# CBASS_MEM_CBASS_ISC_45830000h register map
Vendor: Texas Instruments
Peripheral module from a debugger description file (folder AM275x).
Registers are 32-bit, read-write, reset 0x0 unless marked. A register's access mark holds for its fields unless they carry their own. Offsets are as the file gives them; lines under a group give offsets from that group; [hi:lo] are bit positions; {n}, {i} and the like mark numbered series; 'fields as' and 'values as' point back to an identical list; <NAME> marks a mode.

## cbass_isc
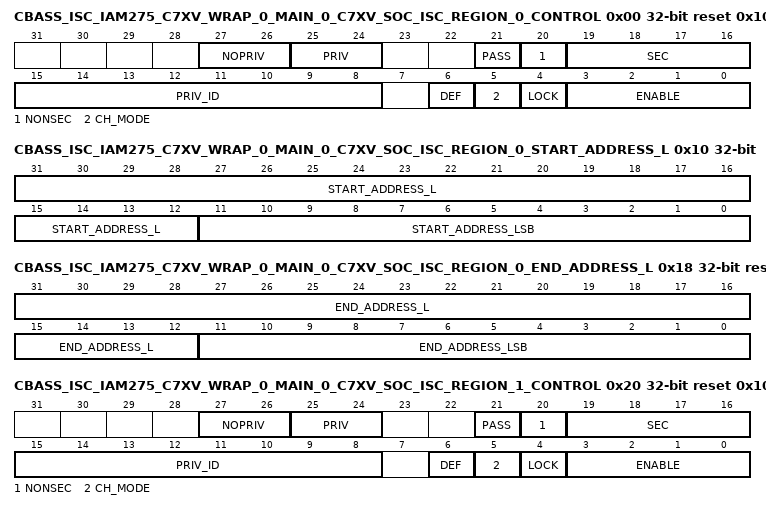
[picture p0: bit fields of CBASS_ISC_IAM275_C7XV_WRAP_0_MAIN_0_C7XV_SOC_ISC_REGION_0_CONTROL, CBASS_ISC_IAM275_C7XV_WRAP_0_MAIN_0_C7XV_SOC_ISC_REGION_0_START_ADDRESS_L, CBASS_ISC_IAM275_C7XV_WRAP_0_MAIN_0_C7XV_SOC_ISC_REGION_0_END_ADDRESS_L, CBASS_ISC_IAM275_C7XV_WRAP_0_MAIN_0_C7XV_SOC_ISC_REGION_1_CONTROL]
0x00 CBASS_ISC_IAM275_C7XV_WRAP_0_MAIN_0_C7XV_SOC_ISC_REGION_0_CONTROL access not given reset 0x102000 — The ISC Region 0 Control Register defines the control fields for the initiator Iam275_c7xv_wrap_0_main_0.c7xv_soc region 0 ISC.
  [27:26] NOPRIV rw — Clear output priv attribute. If each bit is set then the outgoing priv bit is cleared. Reset Source: domain_default_rst_mod_g_rst_n
  [25:24] PRIV rw — Set outgoing priv attribute. If each bit is set then the outgoing priv bit is set. Reset Source: domain_default_rst_mod_g_rst_n
  [21] PASS rw — No privID replacement, pass through value. Reset Source: domain_default_rst_mod_g_rst_n
  [20] NONSEC rw — Make outgoing non-secure. Reset Source: domain_default_rst_mod_g_rst_n
  [19:16] SEC rw — Make outgoing secure. A value of 0xA enables, others disable. Reset Source: domain_default_rst_mod_g_rst_n
  [15:8] PRIV_ID rw — Priv ID. Reset Source: domain_default_rst_mod_g_rst_n
  [6] DEF ro — Default region indication. The default region is used when all other regions do not match. Reset Source: domain_default_rst_mod_g_rst_n
  [5] CH_MODE rw — Enable channel mode to match region to a chanid value. Otherwise use address mode to match region to an address range. Reset Source: domain_default_rst_mod_g_rst_n
  [4] LOCK — Lock region. Once set the region values cannot be modified. Reset Source: domain_default_rst_mod_g_rst_n (access R/W1TS)
  [3:0] ENABLE rw — Enable region. A value of 0xA enables, others disable. Reset Source: domain_default_rst_mod_g_rst_n
0x10 CBASS_ISC_IAM275_C7XV_WRAP_0_MAIN_0_C7XV_SOC_ISC_REGION_0_START_ADDRESS_L — The ISC Region 0 Start Address Low Register defines the start address bits 31 to 0 for the initiator Iam275_c7xv_wrap_0_main_0.c7xv_soc region 0 ISC.
  [31:12] START_ADDRESS_L — Start address bits 31 to 12. Reset Source: domain_default_rst_mod_g_rst_n
  [11:0] START_ADDRESS_LSB — Start address bits 11 to 0 must be 0 as address must be 4KB aligned in address mode. Can also be channel number in channel mode. Reset Source: domain_default_rst_mod_g_rst_n
0x14 CBASS_ISC_IAM275_C7XV_WRAP_0_MAIN_0_C7XV_SOC_ISC_REGION_0_START_ADDRESS_H — The ISC Region 0 Start Address High Register defines the start address bits 47 to 32 for the initiator Iam275_c7xv_wrap_0_main_0.c7xv_soc region 0 ISC.
  [15:0] START_ADDRESS_H — Start address bits 47 to 32. Reset Source: domain_default_rst_mod_g_rst_n
0x18 CBASS_ISC_IAM275_C7XV_WRAP_0_MAIN_0_C7XV_SOC_ISC_REGION_0_END_ADDRESS_L access per field reset 0xFFF — The ISC Region 0 End Address Low Register defines the end included address bits 31 to 0 for the initiator Iam275_c7xv_wrap_0_main_0.c7xv_soc region 0 ISC.
  [31:12] END_ADDRESS_L rw — End address bits 31 to 12 to include in the match. Reset Source: domain_default_rst_mod_g_rst_n
  [11:0] END_ADDRESS_LSB ro — End address bits 11 to 0 are forced to Fs as address must be 4KB aligned. Reset Source: domain_default_rst_mod_g_rst_n
0x1C CBASS_ISC_IAM275_C7XV_WRAP_0_MAIN_0_C7XV_SOC_ISC_REGION_0_END_ADDRESS_H — The ISC Region 0 End Address High Register defines the end address bits 47 to 32 for the initiator Iam275_c7xv_wrap_0_main_0.c7xv_soc region 0 ISC.
  [15:0] END_ADDRESS_H — End address bits 47 to 32. Reset Source: domain_default_rst_mod_g_rst_n
0x20 CBASS_ISC_IAM275_C7XV_WRAP_0_MAIN_0_C7XV_SOC_ISC_REGION_1_CONTROL access not given reset 0x102000 — The ISC Region 1 Control Register defines the control fields for the initiator Iam275_c7xv_wrap_0_main_0.c7xv_soc region 1 ISC.
  fields as CBASS_ISC_IAM275_C7XV_WRAP_0_MAIN_0_C7XV_SOC_ISC_REGION_0_CONTROL
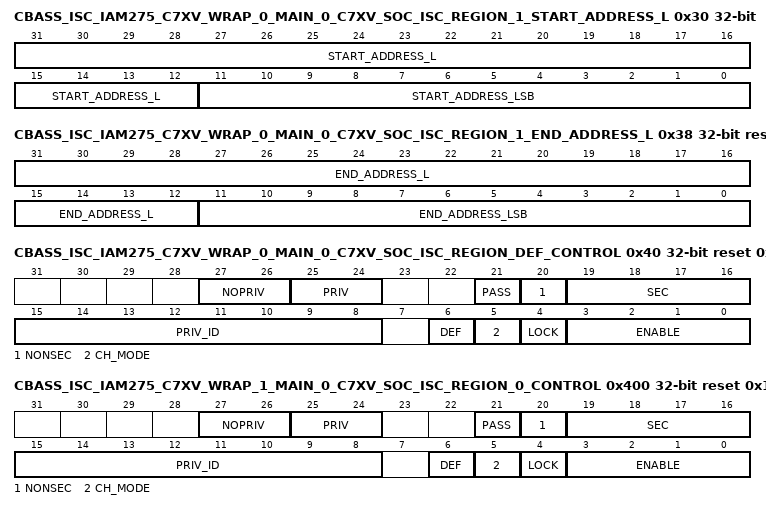
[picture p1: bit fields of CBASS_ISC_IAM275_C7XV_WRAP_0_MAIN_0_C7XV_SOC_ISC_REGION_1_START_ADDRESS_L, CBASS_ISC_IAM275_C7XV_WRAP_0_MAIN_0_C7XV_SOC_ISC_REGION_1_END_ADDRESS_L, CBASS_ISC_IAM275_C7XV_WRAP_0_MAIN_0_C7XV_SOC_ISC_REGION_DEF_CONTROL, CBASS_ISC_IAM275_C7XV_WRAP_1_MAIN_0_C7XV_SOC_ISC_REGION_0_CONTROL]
0x30 CBASS_ISC_IAM275_C7XV_WRAP_0_MAIN_0_C7XV_SOC_ISC_REGION_1_START_ADDRESS_L — The ISC Region 1 Start Address Low Register defines the start address bits 31 to 0 for the initiator Iam275_c7xv_wrap_0_main_0.c7xv_soc region 1 ISC.
  fields as CBASS_ISC_IAM275_C7XV_WRAP_0_MAIN_0_C7XV_SOC_ISC_REGION_0_START_ADDRESS_L
0x34 CBASS_ISC_IAM275_C7XV_WRAP_0_MAIN_0_C7XV_SOC_ISC_REGION_1_START_ADDRESS_H — The ISC Region 1 Start Address High Register defines the start address bits 47 to 32 for the initiator Iam275_c7xv_wrap_0_main_0.c7xv_soc region 1 ISC.
  fields as CBASS_ISC_IAM275_C7XV_WRAP_0_MAIN_0_C7XV_SOC_ISC_REGION_0_START_ADDRESS_H
0x38 CBASS_ISC_IAM275_C7XV_WRAP_0_MAIN_0_C7XV_SOC_ISC_REGION_1_END_ADDRESS_L access per field reset 0xFFF — The ISC Region 1 End Address Low Register defines the end included address bits 31 to 0 for the initiator Iam275_c7xv_wrap_0_main_0.c7xv_soc region 1 ISC.
  fields as CBASS_ISC_IAM275_C7XV_WRAP_0_MAIN_0_C7XV_SOC_ISC_REGION_0_END_ADDRESS_L
0x3C CBASS_ISC_IAM275_C7XV_WRAP_0_MAIN_0_C7XV_SOC_ISC_REGION_1_END_ADDRESS_H — The ISC Region 1 End Address High Register defines the end address bits 47 to 32 for the initiator Iam275_c7xv_wrap_0_main_0.c7xv_soc region 1 ISC.
  fields as CBASS_ISC_IAM275_C7XV_WRAP_0_MAIN_0_C7XV_SOC_ISC_REGION_0_END_ADDRESS_H
0x40 CBASS_ISC_IAM275_C7XV_WRAP_0_MAIN_0_C7XV_SOC_ISC_REGION_DEF_CONTROL access not given reset 0x10204A — The ISC Default Region Control Register defines the control fields for the initiator Iam275_c7xv_wrap_0_main_0.c7xv_soc region 2 ISC.
  [27:26] NOPRIV rw — Clear output priv attribute. If each bit is set then the outgoing priv bit is cleared, else the bit is unchanged. Do not set both priv and nopriv for the same bit. Reset Source: domain_default_rst_mod_g_rst_n
  [25:24] PRIV rw — Set outgoing priv attribute. If each bit is set then the outgoing priv bit is set, else the bit is unchanged. Do not set both priv and nopriv for the same bit. Reset Source: domain_default_rst_mod_g_rst_n
  [21] PASS rw — No privID replacement. A value of 1 will pass through privid value. A value of 0 will replace privid with priv_id field value. Reset Source: domain_default_rst_mod_g_rst_n
  [20] NONSEC rw — Make outgoing non-secure. A value of 1 forces secure clear, others do nothing. Do not set both sec and nonsec. Reset Source: domain_default_rst_mod_g_rst_n
  [19:16] SEC rw — Make outgoing secure. A value of 0xA forces secure set, others do nothing. Do not set both sec and nonsec. Reset Source: domain_default_rst_mod_g_rst_n
  [15:8] PRIV_ID rw — Priv ID value to use if pass is 0. Reset Source: domain_default_rst_mod_g_rst_n
  [6] DEF ro — Default region indication. The default region is used when all other regions do not match. Reset Source: domain_default_rst_mod_g_rst_n
  [5] CH_MODE ro — Enable channel mode to match region to a chanid value. Otherwise use address mode to match region to an address range. Reset Source: domain_default_rst_mod_g_rst_n
  [4] LOCK — Lock region. Once set, the region values cannot be modified. Reset Source: domain_default_rst_mod_g_rst_n (access R/W1TS)
  [3:0] ENABLE ro — Enable region. A value of 0xA enables, others disable. Reset Source: domain_default_rst_mod_g_rst_n
0x400 CBASS_ISC_IAM275_C7XV_WRAP_1_MAIN_0_C7XV_SOC_ISC_REGION_0_CONTROL access not given reset 0x102100 — The ISC Region 0 Control Register defines the control fields for the initiator Iam275_c7xv_wrap_1_main_0.c7xv_soc region 0 ISC.
  fields as CBASS_ISC_IAM275_C7XV_WRAP_0_MAIN_0_C7XV_SOC_ISC_REGION_0_CONTROL
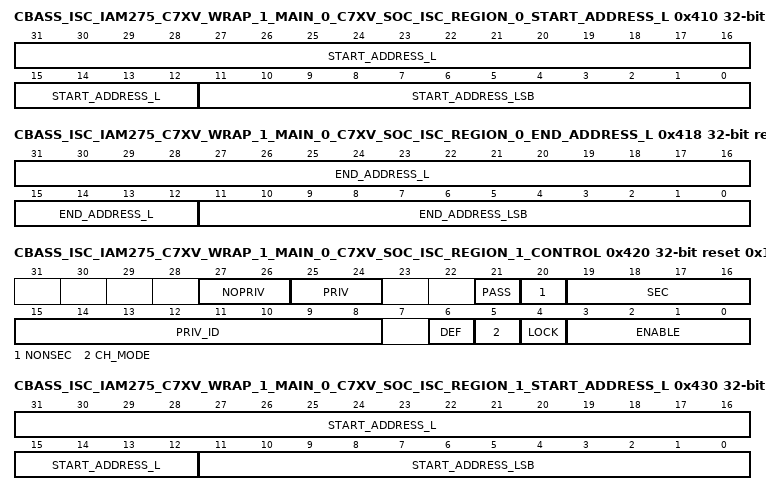
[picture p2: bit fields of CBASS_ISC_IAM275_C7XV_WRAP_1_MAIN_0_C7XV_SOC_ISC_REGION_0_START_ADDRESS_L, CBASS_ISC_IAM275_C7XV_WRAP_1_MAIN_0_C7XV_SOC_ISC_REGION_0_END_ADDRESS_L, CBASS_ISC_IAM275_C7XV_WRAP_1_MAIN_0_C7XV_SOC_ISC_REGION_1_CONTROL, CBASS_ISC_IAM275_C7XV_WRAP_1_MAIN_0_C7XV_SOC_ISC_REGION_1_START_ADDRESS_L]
0x410 CBASS_ISC_IAM275_C7XV_WRAP_1_MAIN_0_C7XV_SOC_ISC_REGION_0_START_ADDRESS_L — The ISC Region 0 Start Address Low Register defines the start address bits 31 to 0 for the initiator Iam275_c7xv_wrap_1_main_0.c7xv_soc region 0 ISC.
  fields as CBASS_ISC_IAM275_C7XV_WRAP_0_MAIN_0_C7XV_SOC_ISC_REGION_0_START_ADDRESS_L
0x414 CBASS_ISC_IAM275_C7XV_WRAP_1_MAIN_0_C7XV_SOC_ISC_REGION_0_START_ADDRESS_H — The ISC Region 0 Start Address High Register defines the start address bits 47 to 32 for the initiator Iam275_c7xv_wrap_1_main_0.c7xv_soc region 0 ISC.
  fields as CBASS_ISC_IAM275_C7XV_WRAP_0_MAIN_0_C7XV_SOC_ISC_REGION_0_START_ADDRESS_H
0x418 CBASS_ISC_IAM275_C7XV_WRAP_1_MAIN_0_C7XV_SOC_ISC_REGION_0_END_ADDRESS_L access per field reset 0xFFF — The ISC Region 0 End Address Low Register defines the end included address bits 31 to 0 for the initiator Iam275_c7xv_wrap_1_main_0.c7xv_soc region 0 ISC.
  fields as CBASS_ISC_IAM275_C7XV_WRAP_0_MAIN_0_C7XV_SOC_ISC_REGION_0_END_ADDRESS_L
0x41C CBASS_ISC_IAM275_C7XV_WRAP_1_MAIN_0_C7XV_SOC_ISC_REGION_0_END_ADDRESS_H — The ISC Region 0 End Address High Register defines the end address bits 47 to 32 for the initiator Iam275_c7xv_wrap_1_main_0.c7xv_soc region 0 ISC.
  fields as CBASS_ISC_IAM275_C7XV_WRAP_0_MAIN_0_C7XV_SOC_ISC_REGION_0_END_ADDRESS_H
0x420 CBASS_ISC_IAM275_C7XV_WRAP_1_MAIN_0_C7XV_SOC_ISC_REGION_1_CONTROL access not given reset 0x102100 — The ISC Region 1 Control Register defines the control fields for the initiator Iam275_c7xv_wrap_1_main_0.c7xv_soc region 1 ISC.
  fields as CBASS_ISC_IAM275_C7XV_WRAP_0_MAIN_0_C7XV_SOC_ISC_REGION_0_CONTROL
0x430 CBASS_ISC_IAM275_C7XV_WRAP_1_MAIN_0_C7XV_SOC_ISC_REGION_1_START_ADDRESS_L — The ISC Region 1 Start Address Low Register defines the start address bits 31 to 0 for the initiator Iam275_c7xv_wrap_1_main_0.c7xv_soc region 1 ISC.
  fields as CBASS_ISC_IAM275_C7XV_WRAP_0_MAIN_0_C7XV_SOC_ISC_REGION_0_START_ADDRESS_L
0x434 CBASS_ISC_IAM275_C7XV_WRAP_1_MAIN_0_C7XV_SOC_ISC_REGION_1_START_ADDRESS_H — The ISC Region 1 Start Address High Register defines the start address bits 47 to 32 for the initiator Iam275_c7xv_wrap_1_main_0.c7xv_soc region 1 ISC.
  fields as CBASS_ISC_IAM275_C7XV_WRAP_0_MAIN_0_C7XV_SOC_ISC_REGION_0_START_ADDRESS_H
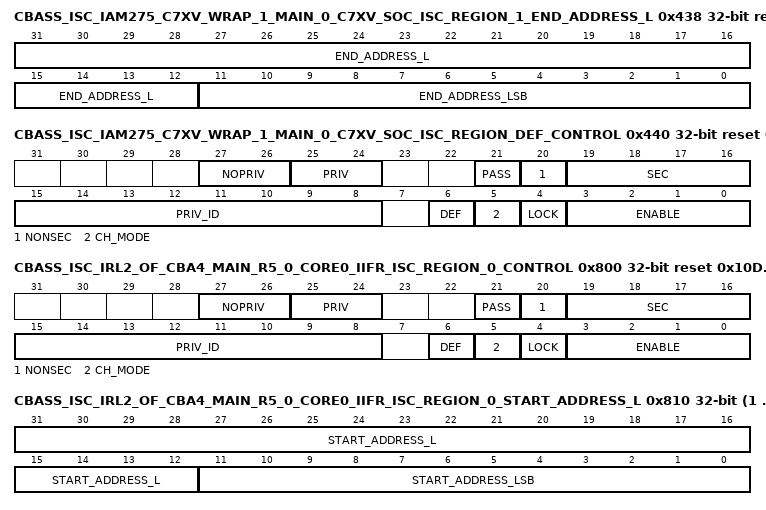
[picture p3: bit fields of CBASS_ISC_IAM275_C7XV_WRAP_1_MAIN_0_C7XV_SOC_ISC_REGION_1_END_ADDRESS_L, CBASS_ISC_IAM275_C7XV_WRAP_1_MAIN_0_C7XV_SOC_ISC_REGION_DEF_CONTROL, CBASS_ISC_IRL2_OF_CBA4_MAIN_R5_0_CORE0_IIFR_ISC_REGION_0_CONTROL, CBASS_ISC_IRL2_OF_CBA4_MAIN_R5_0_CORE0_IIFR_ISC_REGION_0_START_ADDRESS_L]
0x438 CBASS_ISC_IAM275_C7XV_WRAP_1_MAIN_0_C7XV_SOC_ISC_REGION_1_END_ADDRESS_L access per field reset 0xFFF — The ISC Region 1 End Address Low Register defines the end included address bits 31 to 0 for the initiator Iam275_c7xv_wrap_1_main_0.c7xv_soc region 1 ISC.
  fields as CBASS_ISC_IAM275_C7XV_WRAP_0_MAIN_0_C7XV_SOC_ISC_REGION_0_END_ADDRESS_L
0x43C CBASS_ISC_IAM275_C7XV_WRAP_1_MAIN_0_C7XV_SOC_ISC_REGION_1_END_ADDRESS_H — The ISC Region 1 End Address High Register defines the end address bits 47 to 32 for the initiator Iam275_c7xv_wrap_1_main_0.c7xv_soc region 1 ISC.
  fields as CBASS_ISC_IAM275_C7XV_WRAP_0_MAIN_0_C7XV_SOC_ISC_REGION_0_END_ADDRESS_H
0x440 CBASS_ISC_IAM275_C7XV_WRAP_1_MAIN_0_C7XV_SOC_ISC_REGION_DEF_CONTROL access not given reset 0x10214A — The ISC Default Region Control Register defines the control fields for the initiator Iam275_c7xv_wrap_1_main_0.c7xv_soc region 2 ISC.
  fields as CBASS_ISC_IAM275_C7XV_WRAP_0_MAIN_0_C7XV_SOC_ISC_REGION_DEF_CONTROL
{0x800+0x20*i} CBASS_ISC_IRL2_OF_CBA4_MAIN_R5_0_CORE0_IIFR_ISC_REGION_{i}_CONTROL access not given reset 0x10D800 (i=0..3) — The ISC Region {i} Control Register defines the control fields for the initiator Irl2_of_cba4_main_r5_0_core0.iifr region {i} ISC.
  fields as CBASS_ISC_IAM275_C7XV_WRAP_0_MAIN_0_C7XV_SOC_ISC_REGION_0_CONTROL
{0x810+0x20*i} CBASS_ISC_IRL2_OF_CBA4_MAIN_R5_0_CORE0_IIFR_ISC_REGION_{i}_START_ADDRESS_L (i=0..3) — The ISC Region {i} Start Address Low Register defines the start address bits 31 to 0 for the initiator Irl2_of_cba4_main_r5_0_core0.iifr region {i} ISC.
  fields as CBASS_ISC_IAM275_C7XV_WRAP_0_MAIN_0_C7XV_SOC_ISC_REGION_0_START_ADDRESS_L
{0x814+0x20*i} CBASS_ISC_IRL2_OF_CBA4_MAIN_R5_0_CORE0_IIFR_ISC_REGION_{i}_START_ADDRESS_H (i=0..3) — The ISC Region {i} Start Address High Register defines the start address bits 47 to 32 for the initiator Irl2_of_cba4_main_r5_0_core0.iifr region {i} ISC.
  fields as CBASS_ISC_IAM275_C7XV_WRAP_0_MAIN_0_C7XV_SOC_ISC_REGION_0_START_ADDRESS_H
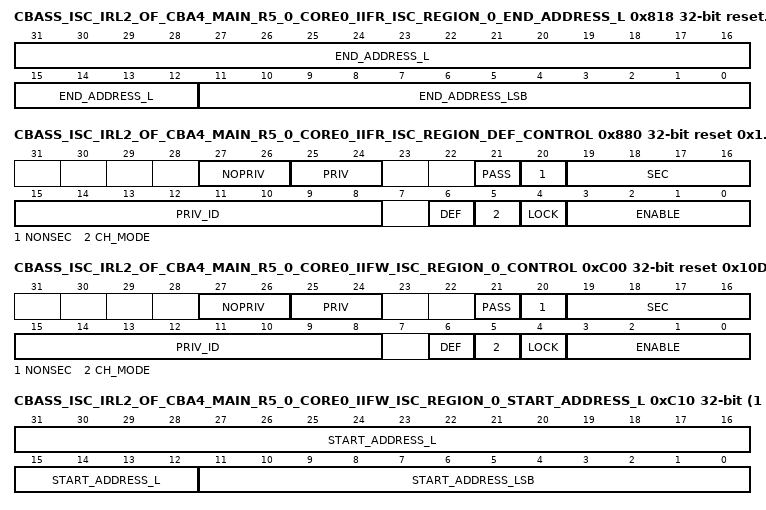
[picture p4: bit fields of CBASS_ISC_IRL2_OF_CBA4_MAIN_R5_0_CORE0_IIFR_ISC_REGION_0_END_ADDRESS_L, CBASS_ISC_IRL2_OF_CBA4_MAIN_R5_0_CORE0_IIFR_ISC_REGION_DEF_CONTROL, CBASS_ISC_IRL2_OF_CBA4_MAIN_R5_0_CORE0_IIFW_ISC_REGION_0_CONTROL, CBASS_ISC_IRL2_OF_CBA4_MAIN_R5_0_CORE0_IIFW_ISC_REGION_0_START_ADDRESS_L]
{0x818+0x20*i} CBASS_ISC_IRL2_OF_CBA4_MAIN_R5_0_CORE0_IIFR_ISC_REGION_{i}_END_ADDRESS_L access per field reset 0xFFF (i=0..3) — The ISC Region {i} End Address Low Register defines the end included address bits 31 to 0 for the initiator Irl2_of_cba4_main_r5_0_core0.iifr region {i} ISC.
  fields as CBASS_ISC_IAM275_C7XV_WRAP_0_MAIN_0_C7XV_SOC_ISC_REGION_0_END_ADDRESS_L
{0x81C+0x20*i} CBASS_ISC_IRL2_OF_CBA4_MAIN_R5_0_CORE0_IIFR_ISC_REGION_{i}_END_ADDRESS_H (i=0..3) — The ISC Region {i} End Address High Register defines the end address bits 47 to 32 for the initiator Irl2_of_cba4_main_r5_0_core0.iifr region {i} ISC.
  fields as CBASS_ISC_IAM275_C7XV_WRAP_0_MAIN_0_C7XV_SOC_ISC_REGION_0_END_ADDRESS_H
0x880 CBASS_ISC_IRL2_OF_CBA4_MAIN_R5_0_CORE0_IIFR_ISC_REGION_DEF_CONTROL access not given reset 0x10D84A — The ISC Default Region Control Register defines the control fields for the initiator Irl2_of_cba4_main_r5_0_core0.iifr region 4 ISC.
  fields as CBASS_ISC_IAM275_C7XV_WRAP_0_MAIN_0_C7XV_SOC_ISC_REGION_DEF_CONTROL
{0xC00+0x20*i} CBASS_ISC_IRL2_OF_CBA4_MAIN_R5_0_CORE0_IIFW_ISC_REGION_{i}_CONTROL access not given reset 0x10D800 (i=0..3) — The ISC Region {i} Control Register defines the control fields for the initiator Irl2_of_cba4_main_r5_0_core0.iifw region {i} ISC.
  fields as CBASS_ISC_IAM275_C7XV_WRAP_0_MAIN_0_C7XV_SOC_ISC_REGION_0_CONTROL
{0xC10+0x20*i} CBASS_ISC_IRL2_OF_CBA4_MAIN_R5_0_CORE0_IIFW_ISC_REGION_{i}_START_ADDRESS_L (i=0..3) — The ISC Region {i} Start Address Low Register defines the start address bits 31 to 0 for the initiator Irl2_of_cba4_main_r5_0_core0.iifw region {i} ISC.
  fields as CBASS_ISC_IAM275_C7XV_WRAP_0_MAIN_0_C7XV_SOC_ISC_REGION_0_START_ADDRESS_L
{0xC14+0x20*i} CBASS_ISC_IRL2_OF_CBA4_MAIN_R5_0_CORE0_IIFW_ISC_REGION_{i}_START_ADDRESS_H (i=0..3) — The ISC Region {i} Start Address High Register defines the start address bits 47 to 32 for the initiator Irl2_of_cba4_main_r5_0_core0.iifw region {i} ISC.
  fields as CBASS_ISC_IAM275_C7XV_WRAP_0_MAIN_0_C7XV_SOC_ISC_REGION_0_START_ADDRESS_H
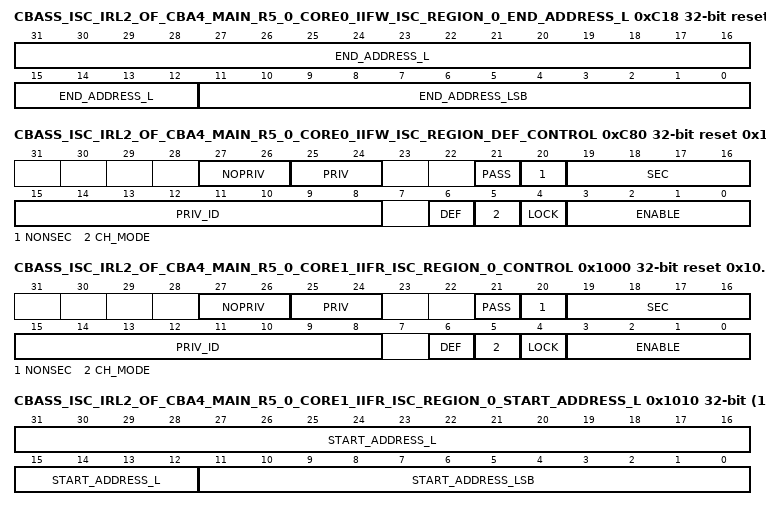
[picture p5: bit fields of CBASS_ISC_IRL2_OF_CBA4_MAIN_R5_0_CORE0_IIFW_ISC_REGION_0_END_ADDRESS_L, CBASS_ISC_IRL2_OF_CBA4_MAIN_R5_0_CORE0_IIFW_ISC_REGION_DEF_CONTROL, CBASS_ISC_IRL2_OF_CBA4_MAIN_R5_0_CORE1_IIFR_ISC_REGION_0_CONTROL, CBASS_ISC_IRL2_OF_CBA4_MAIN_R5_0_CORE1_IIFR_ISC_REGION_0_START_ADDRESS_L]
{0xC18+0x20*i} CBASS_ISC_IRL2_OF_CBA4_MAIN_R5_0_CORE0_IIFW_ISC_REGION_{i}_END_ADDRESS_L access per field reset 0xFFF (i=0..3) — The ISC Region {i} End Address Low Register defines the end included address bits 31 to 0 for the initiator Irl2_of_cba4_main_r5_0_core0.iifw region {i} ISC.
  fields as CBASS_ISC_IAM275_C7XV_WRAP_0_MAIN_0_C7XV_SOC_ISC_REGION_0_END_ADDRESS_L
{0xC1C+0x20*i} CBASS_ISC_IRL2_OF_CBA4_MAIN_R5_0_CORE0_IIFW_ISC_REGION_{i}_END_ADDRESS_H (i=0..3) — The ISC Region {i} End Address High Register defines the end address bits 47 to 32 for the initiator Irl2_of_cba4_main_r5_0_core0.iifw region {i} ISC.
  fields as CBASS_ISC_IAM275_C7XV_WRAP_0_MAIN_0_C7XV_SOC_ISC_REGION_0_END_ADDRESS_H
0xC80 CBASS_ISC_IRL2_OF_CBA4_MAIN_R5_0_CORE0_IIFW_ISC_REGION_DEF_CONTROL access not given reset 0x10D84A — The ISC Default Region Control Register defines the control fields for the initiator Irl2_of_cba4_main_r5_0_core0.iifw region 4 ISC.
  fields as CBASS_ISC_IAM275_C7XV_WRAP_0_MAIN_0_C7XV_SOC_ISC_REGION_DEF_CONTROL
{0x1000+0x20*i} CBASS_ISC_IRL2_OF_CBA4_MAIN_R5_0_CORE1_IIFR_ISC_REGION_{i}_CONTROL access not given reset 0x10D900 (i=0..3) — The ISC Region {i} Control Register defines the control fields for the initiator Irl2_of_cba4_main_r5_0_core1.iifr region {i} ISC.
  fields as CBASS_ISC_IAM275_C7XV_WRAP_0_MAIN_0_C7XV_SOC_ISC_REGION_0_CONTROL
{0x1010+0x20*i} CBASS_ISC_IRL2_OF_CBA4_MAIN_R5_0_CORE1_IIFR_ISC_REGION_{i}_START_ADDRESS_L (i=0..3) — The ISC Region {i} Start Address Low Register defines the start address bits 31 to 0 for the initiator Irl2_of_cba4_main_r5_0_core1.iifr region {i} ISC.
  fields as CBASS_ISC_IAM275_C7XV_WRAP_0_MAIN_0_C7XV_SOC_ISC_REGION_0_START_ADDRESS_L
{0x1014+0x20*i} CBASS_ISC_IRL2_OF_CBA4_MAIN_R5_0_CORE1_IIFR_ISC_REGION_{i}_START_ADDRESS_H (i=0..3) — The ISC Region {i} Start Address High Register defines the start address bits 47 to 32 for the initiator Irl2_of_cba4_main_r5_0_core1.iifr region {i} ISC.
  fields as CBASS_ISC_IAM275_C7XV_WRAP_0_MAIN_0_C7XV_SOC_ISC_REGION_0_START_ADDRESS_H
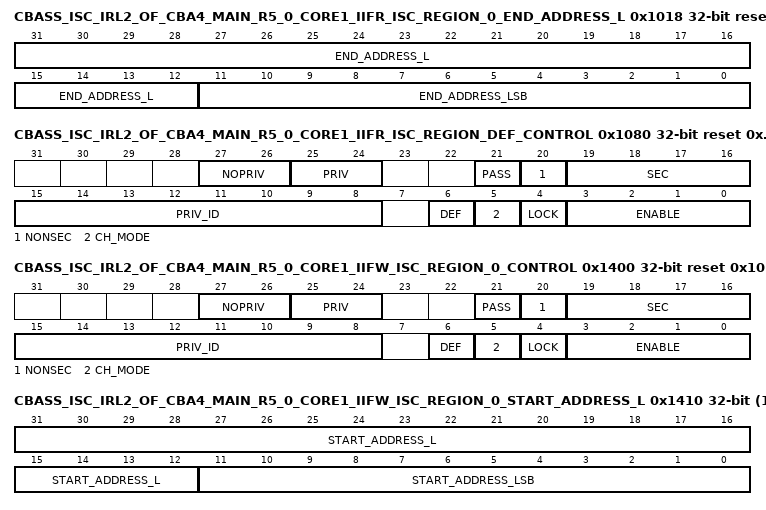
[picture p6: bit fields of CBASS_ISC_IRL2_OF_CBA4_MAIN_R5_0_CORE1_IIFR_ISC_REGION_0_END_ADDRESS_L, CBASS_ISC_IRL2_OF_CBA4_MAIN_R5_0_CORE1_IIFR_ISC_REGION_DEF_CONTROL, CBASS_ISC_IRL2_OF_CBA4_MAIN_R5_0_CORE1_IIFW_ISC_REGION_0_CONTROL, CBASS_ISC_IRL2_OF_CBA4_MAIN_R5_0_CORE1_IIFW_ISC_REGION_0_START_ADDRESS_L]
{0x1018+0x20*i} CBASS_ISC_IRL2_OF_CBA4_MAIN_R5_0_CORE1_IIFR_ISC_REGION_{i}_END_ADDRESS_L access per field reset 0xFFF (i=0..3) — The ISC Region {i} End Address Low Register defines the end included address bits 31 to 0 for the initiator Irl2_of_cba4_main_r5_0_core1.iifr region {i} ISC.
  fields as CBASS_ISC_IAM275_C7XV_WRAP_0_MAIN_0_C7XV_SOC_ISC_REGION_0_END_ADDRESS_L
{0x101C+0x20*i} CBASS_ISC_IRL2_OF_CBA4_MAIN_R5_0_CORE1_IIFR_ISC_REGION_{i}_END_ADDRESS_H (i=0..3) — The ISC Region {i} End Address High Register defines the end address bits 47 to 32 for the initiator Irl2_of_cba4_main_r5_0_core1.iifr region {i} ISC.
  fields as CBASS_ISC_IAM275_C7XV_WRAP_0_MAIN_0_C7XV_SOC_ISC_REGION_0_END_ADDRESS_H
0x1080 CBASS_ISC_IRL2_OF_CBA4_MAIN_R5_0_CORE1_IIFR_ISC_REGION_DEF_CONTROL access not given reset 0x10D94A — The ISC Default Region Control Register defines the control fields for the initiator Irl2_of_cba4_main_r5_0_core1.iifr region 4 ISC.
  fields as CBASS_ISC_IAM275_C7XV_WRAP_0_MAIN_0_C7XV_SOC_ISC_REGION_DEF_CONTROL
{0x1400+0x20*i} CBASS_ISC_IRL2_OF_CBA4_MAIN_R5_0_CORE1_IIFW_ISC_REGION_{i}_CONTROL access not given reset 0x10D900 (i=0..3) — The ISC Region {i} Control Register defines the control fields for the initiator Irl2_of_cba4_main_r5_0_core1.iifw region {i} ISC.
  fields as CBASS_ISC_IAM275_C7XV_WRAP_0_MAIN_0_C7XV_SOC_ISC_REGION_0_CONTROL
{0x1410+0x20*i} CBASS_ISC_IRL2_OF_CBA4_MAIN_R5_0_CORE1_IIFW_ISC_REGION_{i}_START_ADDRESS_L (i=0..3) — The ISC Region {i} Start Address Low Register defines the start address bits 31 to 0 for the initiator Irl2_of_cba4_main_r5_0_core1.iifw region {i} ISC.
  fields as CBASS_ISC_IAM275_C7XV_WRAP_0_MAIN_0_C7XV_SOC_ISC_REGION_0_START_ADDRESS_L
{0x1414+0x20*i} CBASS_ISC_IRL2_OF_CBA4_MAIN_R5_0_CORE1_IIFW_ISC_REGION_{i}_START_ADDRESS_H (i=0..3) — The ISC Region {i} Start Address High Register defines the start address bits 47 to 32 for the initiator Irl2_of_cba4_main_r5_0_core1.iifw region {i} ISC.
  fields as CBASS_ISC_IAM275_C7XV_WRAP_0_MAIN_0_C7XV_SOC_ISC_REGION_0_START_ADDRESS_H
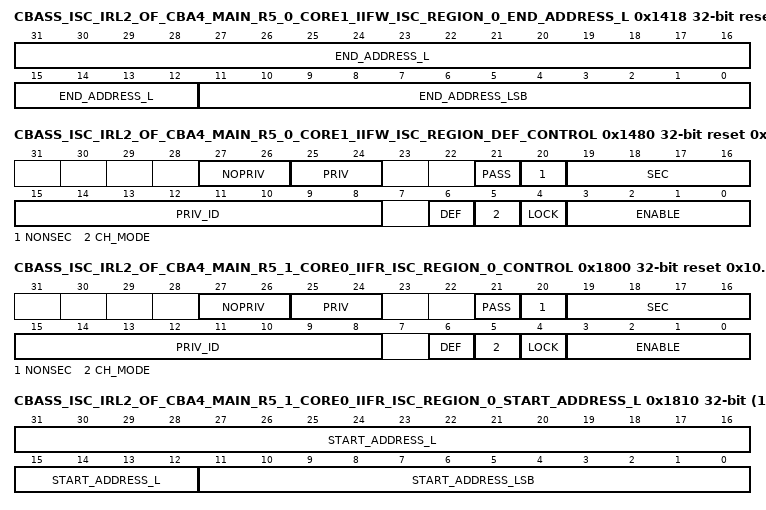
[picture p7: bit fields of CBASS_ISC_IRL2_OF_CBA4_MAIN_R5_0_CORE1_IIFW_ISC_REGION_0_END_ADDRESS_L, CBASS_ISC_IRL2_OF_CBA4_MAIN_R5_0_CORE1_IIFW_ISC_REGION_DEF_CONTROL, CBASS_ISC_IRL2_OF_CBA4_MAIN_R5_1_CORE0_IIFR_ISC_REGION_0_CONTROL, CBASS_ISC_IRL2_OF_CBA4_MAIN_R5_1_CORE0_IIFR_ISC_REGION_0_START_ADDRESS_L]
{0x1418+0x20*i} CBASS_ISC_IRL2_OF_CBA4_MAIN_R5_0_CORE1_IIFW_ISC_REGION_{i}_END_ADDRESS_L access per field reset 0xFFF (i=0..3) — The ISC Region {i} End Address Low Register defines the end included address bits 31 to 0 for the initiator Irl2_of_cba4_main_r5_0_core1.iifw region {i} ISC.
  fields as CBASS_ISC_IAM275_C7XV_WRAP_0_MAIN_0_C7XV_SOC_ISC_REGION_0_END_ADDRESS_L
{0x141C+0x20*i} CBASS_ISC_IRL2_OF_CBA4_MAIN_R5_0_CORE1_IIFW_ISC_REGION_{i}_END_ADDRESS_H (i=0..3) — The ISC Region {i} End Address High Register defines the end address bits 47 to 32 for the initiator Irl2_of_cba4_main_r5_0_core1.iifw region {i} ISC.
  fields as CBASS_ISC_IAM275_C7XV_WRAP_0_MAIN_0_C7XV_SOC_ISC_REGION_0_END_ADDRESS_H
0x1480 CBASS_ISC_IRL2_OF_CBA4_MAIN_R5_0_CORE1_IIFW_ISC_REGION_DEF_CONTROL access not given reset 0x10D94A — The ISC Default Region Control Register defines the control fields for the initiator Irl2_of_cba4_main_r5_0_core1.iifw region 4 ISC.
  fields as CBASS_ISC_IAM275_C7XV_WRAP_0_MAIN_0_C7XV_SOC_ISC_REGION_DEF_CONTROL
{0x1800+0x20*i} CBASS_ISC_IRL2_OF_CBA4_MAIN_R5_1_CORE0_IIFR_ISC_REGION_{i}_CONTROL access not given reset 0x10DB00 (i=0..3) — The ISC Region {i} Control Register defines the control fields for the initiator Irl2_of_cba4_main_r5_1_core0.iifr region {i} ISC.
  fields as CBASS_ISC_IAM275_C7XV_WRAP_0_MAIN_0_C7XV_SOC_ISC_REGION_0_CONTROL
{0x1810+0x20*i} CBASS_ISC_IRL2_OF_CBA4_MAIN_R5_1_CORE0_IIFR_ISC_REGION_{i}_START_ADDRESS_L (i=0..3) — The ISC Region {i} Start Address Low Register defines the start address bits 31 to 0 for the initiator Irl2_of_cba4_main_r5_1_core0.iifr region {i} ISC.
  fields as CBASS_ISC_IAM275_C7XV_WRAP_0_MAIN_0_C7XV_SOC_ISC_REGION_0_START_ADDRESS_L
{0x1814+0x20*i} CBASS_ISC_IRL2_OF_CBA4_MAIN_R5_1_CORE0_IIFR_ISC_REGION_{i}_START_ADDRESS_H (i=0..3) — The ISC Region {i} Start Address High Register defines the start address bits 47 to 32 for the initiator Irl2_of_cba4_main_r5_1_core0.iifr region {i} ISC.
  fields as CBASS_ISC_IAM275_C7XV_WRAP_0_MAIN_0_C7XV_SOC_ISC_REGION_0_START_ADDRESS_H
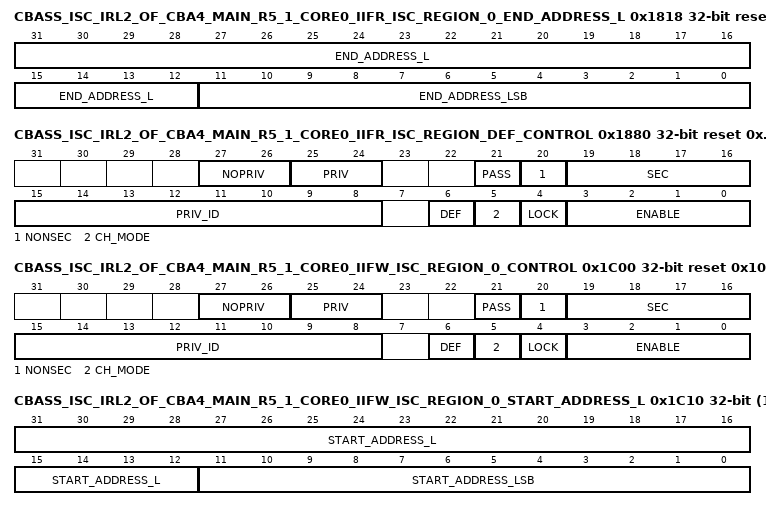
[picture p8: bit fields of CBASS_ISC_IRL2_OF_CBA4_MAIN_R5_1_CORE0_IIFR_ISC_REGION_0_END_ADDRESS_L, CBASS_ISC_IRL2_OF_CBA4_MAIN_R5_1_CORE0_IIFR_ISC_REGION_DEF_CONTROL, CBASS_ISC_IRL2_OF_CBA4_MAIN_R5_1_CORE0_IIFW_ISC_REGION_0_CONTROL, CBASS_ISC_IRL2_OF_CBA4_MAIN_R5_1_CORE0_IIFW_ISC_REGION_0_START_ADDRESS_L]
{0x1818+0x20*i} CBASS_ISC_IRL2_OF_CBA4_MAIN_R5_1_CORE0_IIFR_ISC_REGION_{i}_END_ADDRESS_L access per field reset 0xFFF (i=0..3) — The ISC Region {i} End Address Low Register defines the end included address bits 31 to 0 for the initiator Irl2_of_cba4_main_r5_1_core0.iifr region {i} ISC.
  fields as CBASS_ISC_IAM275_C7XV_WRAP_0_MAIN_0_C7XV_SOC_ISC_REGION_0_END_ADDRESS_L
{0x181C+0x20*i} CBASS_ISC_IRL2_OF_CBA4_MAIN_R5_1_CORE0_IIFR_ISC_REGION_{i}_END_ADDRESS_H (i=0..3) — The ISC Region {i} End Address High Register defines the end address bits 47 to 32 for the initiator Irl2_of_cba4_main_r5_1_core0.iifr region {i} ISC.
  fields as CBASS_ISC_IAM275_C7XV_WRAP_0_MAIN_0_C7XV_SOC_ISC_REGION_0_END_ADDRESS_H
0x1880 CBASS_ISC_IRL2_OF_CBA4_MAIN_R5_1_CORE0_IIFR_ISC_REGION_DEF_CONTROL access not given reset 0x10DB4A — The ISC Default Region Control Register defines the control fields for the initiator Irl2_of_cba4_main_r5_1_core0.iifr region 4 ISC.
  fields as CBASS_ISC_IAM275_C7XV_WRAP_0_MAIN_0_C7XV_SOC_ISC_REGION_DEF_CONTROL
{0x1C00+0x20*i} CBASS_ISC_IRL2_OF_CBA4_MAIN_R5_1_CORE0_IIFW_ISC_REGION_{i}_CONTROL access not given reset 0x10DB00 (i=0..3) — The ISC Region {i} Control Register defines the control fields for the initiator Irl2_of_cba4_main_r5_1_core0.iifw region {i} ISC.
  fields as CBASS_ISC_IAM275_C7XV_WRAP_0_MAIN_0_C7XV_SOC_ISC_REGION_0_CONTROL
{0x1C10+0x20*i} CBASS_ISC_IRL2_OF_CBA4_MAIN_R5_1_CORE0_IIFW_ISC_REGION_{i}_START_ADDRESS_L (i=0..3) — The ISC Region {i} Start Address Low Register defines the start address bits 31 to 0 for the initiator Irl2_of_cba4_main_r5_1_core0.iifw region {i} ISC.
  fields as CBASS_ISC_IAM275_C7XV_WRAP_0_MAIN_0_C7XV_SOC_ISC_REGION_0_START_ADDRESS_L
{0x1C14+0x20*i} CBASS_ISC_IRL2_OF_CBA4_MAIN_R5_1_CORE0_IIFW_ISC_REGION_{i}_START_ADDRESS_H (i=0..3) — The ISC Region {i} Start Address High Register defines the start address bits 47 to 32 for the initiator Irl2_of_cba4_main_r5_1_core0.iifw region {i} ISC.
  fields as CBASS_ISC_IAM275_C7XV_WRAP_0_MAIN_0_C7XV_SOC_ISC_REGION_0_START_ADDRESS_H
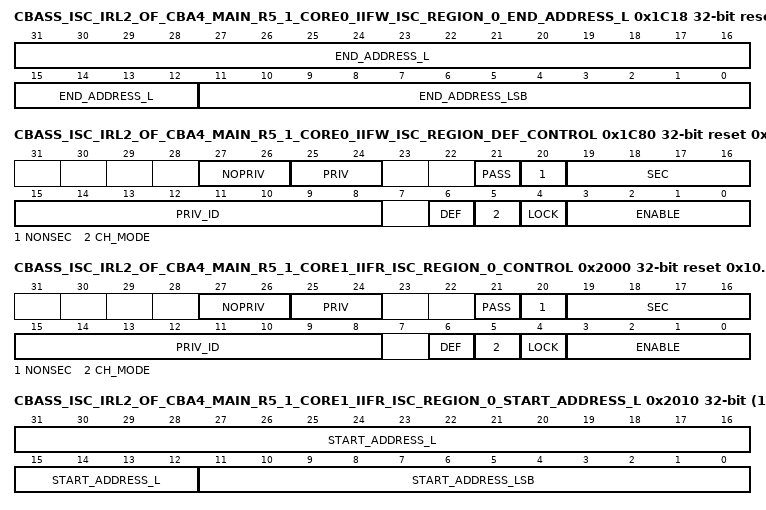
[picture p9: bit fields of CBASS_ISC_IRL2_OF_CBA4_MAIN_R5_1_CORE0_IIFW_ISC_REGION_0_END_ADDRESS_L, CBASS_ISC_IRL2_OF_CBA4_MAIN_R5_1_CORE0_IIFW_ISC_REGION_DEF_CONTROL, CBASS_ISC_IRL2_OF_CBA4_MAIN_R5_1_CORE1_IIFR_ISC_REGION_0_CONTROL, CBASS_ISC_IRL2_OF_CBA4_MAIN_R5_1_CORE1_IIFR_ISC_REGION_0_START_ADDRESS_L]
{0x1C18+0x20*i} CBASS_ISC_IRL2_OF_CBA4_MAIN_R5_1_CORE0_IIFW_ISC_REGION_{i}_END_ADDRESS_L access per field reset 0xFFF (i=0..3) — The ISC Region {i} End Address Low Register defines the end included address bits 31 to 0 for the initiator Irl2_of_cba4_main_r5_1_core0.iifw region {i} ISC.
  fields as CBASS_ISC_IAM275_C7XV_WRAP_0_MAIN_0_C7XV_SOC_ISC_REGION_0_END_ADDRESS_L
{0x1C1C+0x20*i} CBASS_ISC_IRL2_OF_CBA4_MAIN_R5_1_CORE0_IIFW_ISC_REGION_{i}_END_ADDRESS_H (i=0..3) — The ISC Region {i} End Address High Register defines the end address bits 47 to 32 for the initiator Irl2_of_cba4_main_r5_1_core0.iifw region {i} ISC.
  fields as CBASS_ISC_IAM275_C7XV_WRAP_0_MAIN_0_C7XV_SOC_ISC_REGION_0_END_ADDRESS_H
0x1C80 CBASS_ISC_IRL2_OF_CBA4_MAIN_R5_1_CORE0_IIFW_ISC_REGION_DEF_CONTROL access not given reset 0x10DB4A — The ISC Default Region Control Register defines the control fields for the initiator Irl2_of_cba4_main_r5_1_core0.iifw region 4 ISC.
  fields as CBASS_ISC_IAM275_C7XV_WRAP_0_MAIN_0_C7XV_SOC_ISC_REGION_DEF_CONTROL
{0x2000+0x20*i} CBASS_ISC_IRL2_OF_CBA4_MAIN_R5_1_CORE1_IIFR_ISC_REGION_{i}_CONTROL access not given reset 0x10DC00 (i=0..3) — The ISC Region {i} Control Register defines the control fields for the initiator Irl2_of_cba4_main_r5_1_core1.iifr region {i} ISC.
  fields as CBASS_ISC_IAM275_C7XV_WRAP_0_MAIN_0_C7XV_SOC_ISC_REGION_0_CONTROL
{0x2010+0x20*i} CBASS_ISC_IRL2_OF_CBA4_MAIN_R5_1_CORE1_IIFR_ISC_REGION_{i}_START_ADDRESS_L (i=0..3) — The ISC Region {i} Start Address Low Register defines the start address bits 31 to 0 for the initiator Irl2_of_cba4_main_r5_1_core1.iifr region {i} ISC.
  fields as CBASS_ISC_IAM275_C7XV_WRAP_0_MAIN_0_C7XV_SOC_ISC_REGION_0_START_ADDRESS_L
{0x2014+0x20*i} CBASS_ISC_IRL2_OF_CBA4_MAIN_R5_1_CORE1_IIFR_ISC_REGION_{i}_START_ADDRESS_H (i=0..3) — The ISC Region {i} Start Address High Register defines the start address bits 47 to 32 for the initiator Irl2_of_cba4_main_r5_1_core1.iifr region {i} ISC.
  fields as CBASS_ISC_IAM275_C7XV_WRAP_0_MAIN_0_C7XV_SOC_ISC_REGION_0_START_ADDRESS_H
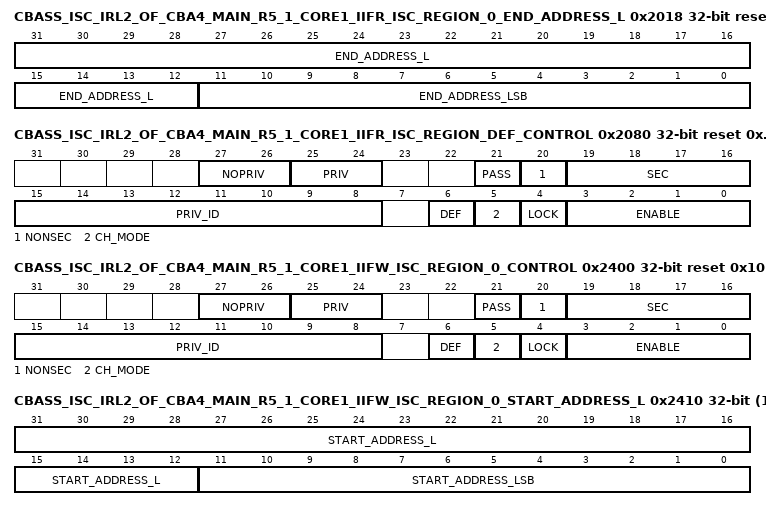
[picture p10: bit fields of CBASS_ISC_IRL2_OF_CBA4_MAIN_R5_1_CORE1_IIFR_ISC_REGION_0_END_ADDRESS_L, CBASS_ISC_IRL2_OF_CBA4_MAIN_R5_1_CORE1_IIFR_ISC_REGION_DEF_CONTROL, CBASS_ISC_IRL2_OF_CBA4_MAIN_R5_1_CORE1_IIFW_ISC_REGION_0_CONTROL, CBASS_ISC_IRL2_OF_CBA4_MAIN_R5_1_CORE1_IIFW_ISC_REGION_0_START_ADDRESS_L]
{0x2018+0x20*i} CBASS_ISC_IRL2_OF_CBA4_MAIN_R5_1_CORE1_IIFR_ISC_REGION_{i}_END_ADDRESS_L access per field reset 0xFFF (i=0..3) — The ISC Region {i} End Address Low Register defines the end included address bits 31 to 0 for the initiator Irl2_of_cba4_main_r5_1_core1.iifr region {i} ISC.
  fields as CBASS_ISC_IAM275_C7XV_WRAP_0_MAIN_0_C7XV_SOC_ISC_REGION_0_END_ADDRESS_L
{0x201C+0x20*i} CBASS_ISC_IRL2_OF_CBA4_MAIN_R5_1_CORE1_IIFR_ISC_REGION_{i}_END_ADDRESS_H (i=0..3) — The ISC Region {i} End Address High Register defines the end address bits 47 to 32 for the initiator Irl2_of_cba4_main_r5_1_core1.iifr region {i} ISC.
  fields as CBASS_ISC_IAM275_C7XV_WRAP_0_MAIN_0_C7XV_SOC_ISC_REGION_0_END_ADDRESS_H
0x2080 CBASS_ISC_IRL2_OF_CBA4_MAIN_R5_1_CORE1_IIFR_ISC_REGION_DEF_CONTROL access not given reset 0x10DC4A — The ISC Default Region Control Register defines the control fields for the initiator Irl2_of_cba4_main_r5_1_core1.iifr region 4 ISC.
  fields as CBASS_ISC_IAM275_C7XV_WRAP_0_MAIN_0_C7XV_SOC_ISC_REGION_DEF_CONTROL
{0x2400+0x20*i} CBASS_ISC_IRL2_OF_CBA4_MAIN_R5_1_CORE1_IIFW_ISC_REGION_{i}_CONTROL access not given reset 0x10DC00 (i=0..3) — The ISC Region {i} Control Register defines the control fields for the initiator Irl2_of_cba4_main_r5_1_core1.iifw region {i} ISC.
  fields as CBASS_ISC_IAM275_C7XV_WRAP_0_MAIN_0_C7XV_SOC_ISC_REGION_0_CONTROL
{0x2410+0x20*i} CBASS_ISC_IRL2_OF_CBA4_MAIN_R5_1_CORE1_IIFW_ISC_REGION_{i}_START_ADDRESS_L (i=0..3) — The ISC Region {i} Start Address Low Register defines the start address bits 31 to 0 for the initiator Irl2_of_cba4_main_r5_1_core1.iifw region {i} ISC.
  fields as CBASS_ISC_IAM275_C7XV_WRAP_0_MAIN_0_C7XV_SOC_ISC_REGION_0_START_ADDRESS_L
{0x2414+0x20*i} CBASS_ISC_IRL2_OF_CBA4_MAIN_R5_1_CORE1_IIFW_ISC_REGION_{i}_START_ADDRESS_H (i=0..3) — The ISC Region {i} Start Address High Register defines the start address bits 47 to 32 for the initiator Irl2_of_cba4_main_r5_1_core1.iifw region {i} ISC.
  fields as CBASS_ISC_IAM275_C7XV_WRAP_0_MAIN_0_C7XV_SOC_ISC_REGION_0_START_ADDRESS_H
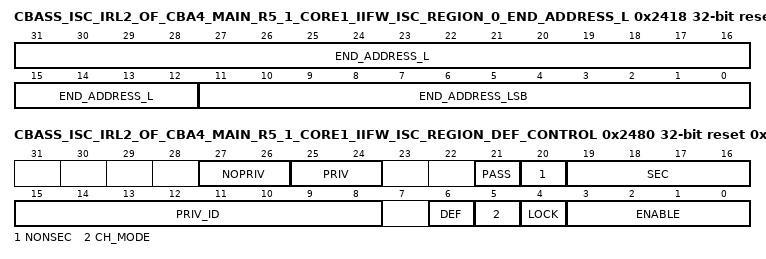
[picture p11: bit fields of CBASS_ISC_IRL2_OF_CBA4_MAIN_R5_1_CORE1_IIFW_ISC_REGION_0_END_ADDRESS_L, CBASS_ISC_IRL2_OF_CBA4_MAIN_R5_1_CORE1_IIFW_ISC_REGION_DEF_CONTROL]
{0x2418+0x20*i} CBASS_ISC_IRL2_OF_CBA4_MAIN_R5_1_CORE1_IIFW_ISC_REGION_{i}_END_ADDRESS_L access per field reset 0xFFF (i=0..3) — The ISC Region {i} End Address Low Register defines the end included address bits 31 to 0 for the initiator Irl2_of_cba4_main_r5_1_core1.iifw region {i} ISC.
  fields as CBASS_ISC_IAM275_C7XV_WRAP_0_MAIN_0_C7XV_SOC_ISC_REGION_0_END_ADDRESS_L
{0x241C+0x20*i} CBASS_ISC_IRL2_OF_CBA4_MAIN_R5_1_CORE1_IIFW_ISC_REGION_{i}_END_ADDRESS_H (i=0..3) — The ISC Region {i} End Address High Register defines the end address bits 47 to 32 for the initiator Irl2_of_cba4_main_r5_1_core1.iifw region {i} ISC.
  fields as CBASS_ISC_IAM275_C7XV_WRAP_0_MAIN_0_C7XV_SOC_ISC_REGION_0_END_ADDRESS_H
0x2480 CBASS_ISC_IRL2_OF_CBA4_MAIN_R5_1_CORE1_IIFW_ISC_REGION_DEF_CONTROL access not given reset 0x10DC4A — The ISC Default Region Control Register defines the control fields for the initiator Irl2_of_cba4_main_r5_1_core1.iifw region 4 ISC.
  fields as CBASS_ISC_IAM275_C7XV_WRAP_0_MAIN_0_C7XV_SOC_ISC_REGION_DEF_CONTROL
